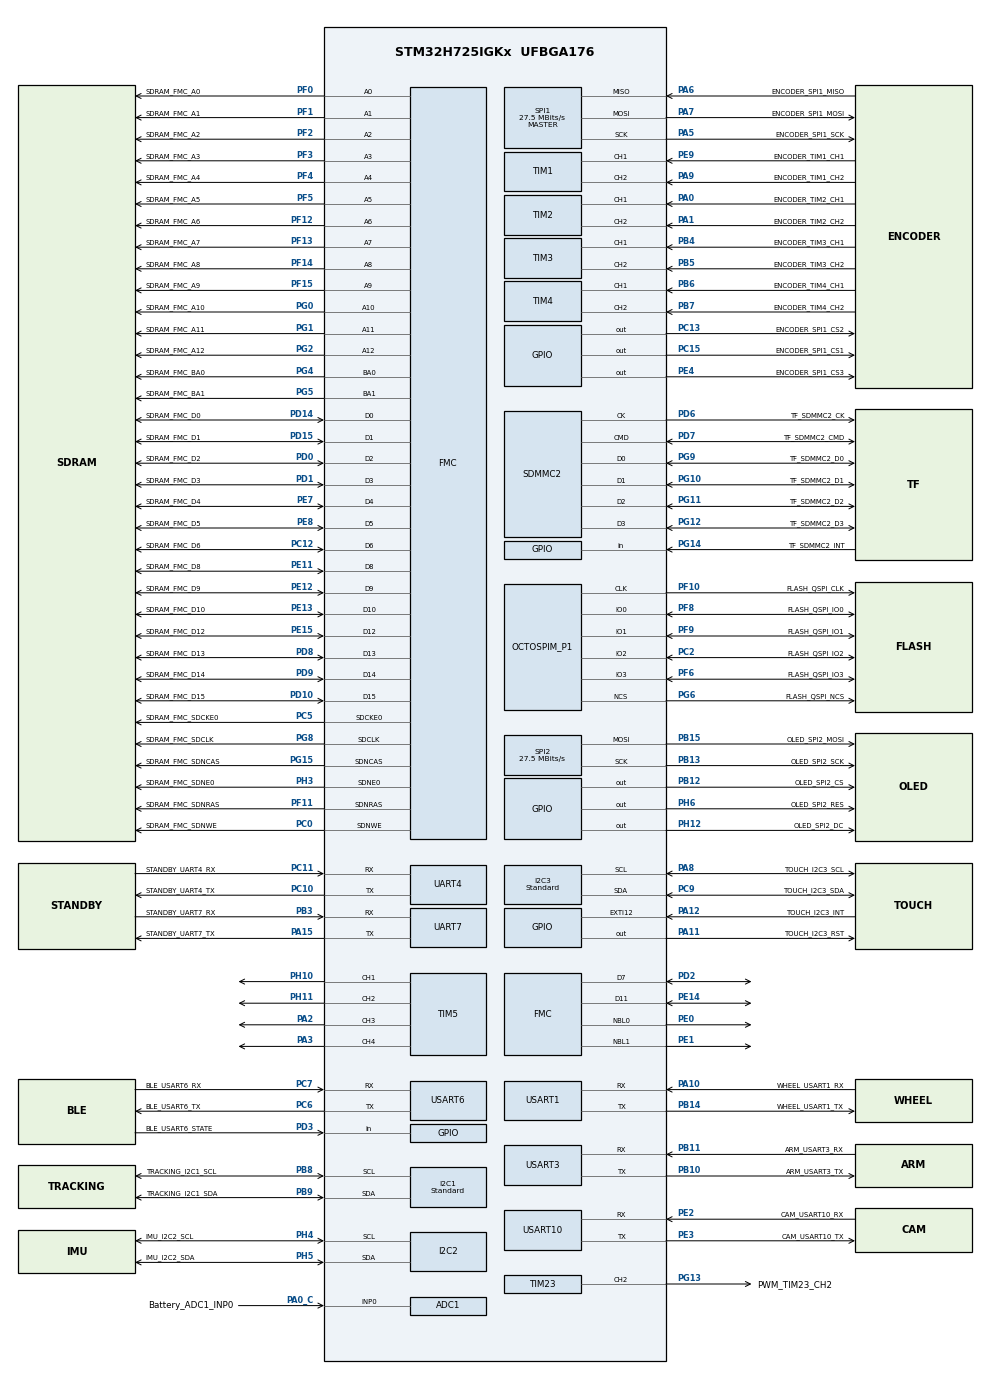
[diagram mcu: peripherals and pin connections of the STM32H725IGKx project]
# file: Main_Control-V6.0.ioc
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ADC1.Channel-0\#ChannelRegularConversion=ADC_CHANNEL_0
ADC1.ContinuousConvMode=ENABLE
ADC1.LowPowerAutoWait=ENABLE
ADC1.NbrOfConversionFlag=1
ADC1.OffsetNumber-0\#ChannelRegularConversion=ADC_OFFSET_NONE
ADC1.OffsetSignedSaturation-0\#ChannelRegularConversion=DISABLE
ADC1.Rank-0\#ChannelRegularConversion=1
ADC1.SamplingTime-0\#ChannelRegularConversion=ADC_SAMPLETIME_810CYCLES_5
ADC1.master=1
Dma.ADC1.8.Direction=DMA_PERIPH_TO_MEMORY
Dma.ADC1.8.EventEnable=DISABLE
Dma.ADC1.8.FIFOMode=DMA_FIFOMODE_DISABLE
Dma.ADC1.8.Instance=DMA2_Stream2
Dma.ADC1.8.MemDataAlignment=DMA_MDATAALIGN_HALFWORD
Dma.ADC1.8.MemInc=DMA_MINC_ENABLE
Dma.ADC1.8.Mode=DMA_CIRCULAR
Dma.ADC1.8.PeriphDataAlignment=DMA_PDATAALIGN_HALFWORD
Dma.ADC1.8.PeriphInc=DMA_PINC_DISABLE
Dma.ADC1.8.Polarity=HAL_DMAMUX_REQ_GEN_RISING
Dma.ADC1.8.Priority=DMA_PRIORITY_LOW
Dma.ADC1.8.RequestNumber=1
Dma.ADC1.8.SignalID=NONE
Dma.ADC1.8.SyncEnable=DISABLE
Dma.ADC1.8.SyncPolarity=HAL_DMAMUX_SYNC_NO_EVENT
Dma.ADC1.8.SyncRequestNumber=1
Dma.ADC1.8.SyncSignalID=NONE
Dma.I2C1_RX.1.Direction=DMA_PERIPH_TO_MEMORY
Dma.I2C1_RX.1.EventEnable=DISABLE
Dma.I2C1_RX.1.FIFOMode=DMA_FIFOMODE_DISABLE
Dma.I2C1_RX.1.Instance=DMA1_Stream1
Dma.I2C1_RX.1.MemDataAlignment=DMA_MDATAALIGN_BYTE
Dma.I2C1_RX.1.MemInc=DMA_MINC_ENABLE
Dma.I2C1_RX.1.Mode=DMA_NORMAL
Dma.I2C1_RX.1.PeriphDataAlignment=DMA_PDATAALIGN_BYTE
Dma.I2C1_RX.1.PeriphInc=DMA_PINC_DISABLE
Dma.I2C1_RX.1.Polarity=HAL_DMAMUX_REQ_GEN_RISING
Dma.I2C1_RX.1.Priority=DMA_PRIORITY_LOW
Dma.I2C1_RX.1.RequestNumber=1
Dma.I2C1_RX.1.SignalID=NONE
Dma.I2C1_RX.1.SyncEnable=DISABLE
Dma.I2C1_RX.1.SyncPolarity=HAL_DMAMUX_SYNC_NO_EVENT
Dma.I2C1_RX.1.SyncRequestNumber=1
Dma.I2C1_RX.1.SyncSignalID=NONE
Dma.I2C1_TX.0.Direction=DMA_MEMORY_TO_PERIPH
Dma.I2C1_TX.0.EventEnable=DISABLE
Dma.I2C1_TX.0.FIFOMode=DMA_FIFOMODE_DISABLE
Dma.I2C1_TX.0.Instance=DMA1_Stream0
Dma.I2C1_TX.0.MemDataAlignment=DMA_MDATAALIGN_BYTE
Dma.I2C1_TX.0.MemInc=DMA_MINC_ENABLE
Dma.I2C1_TX.0.Mode=DMA_NORMAL
Dma.I2C1_TX.0.PeriphDataAlignment=DMA_PDATAALIGN_BYTE
Dma.I2C1_TX.0.PeriphInc=DMA_PINC_DISABLE
Dma.I2C1_TX.0.Polarity=HAL_DMAMUX_REQ_GEN_RISING
Dma.I2C1_TX.0.Priority=DMA_PRIORITY_LOW
Dma.I2C1_TX.0.RequestNumber=1
Dma.I2C1_TX.0.SignalID=NONE
Dma.I2C1_TX.0.SyncEnable=DISABLE
Dma.I2C1_TX.0.SyncPolarity=HAL_DMAMUX_SYNC_NO_EVENT
Dma.I2C1_TX.0.SyncRequestNumber=1
Dma.I2C1_TX.0.SyncSignalID=NONE
Dma.I2C2_RX.3.Direction=DMA_PERIPH_TO_MEMORY
Dma.I2C2_RX.3.EventEnable=DISABLE
Dma.I2C2_RX.3.FIFOMode=DMA_FIFOMODE_DISABLE
Dma.I2C2_RX.3.Instance=DMA1_Stream3
Dma.I2C2_RX.3.MemDataAlignment=DMA_MDATAALIGN_BYTE
Dma.I2C2_RX.3.MemInc=DMA_MINC_ENABLE
Dma.I2C2_RX.3.Mode=DMA_NORMAL
Dma.I2C2_RX.3.PeriphDataAlignment=DMA_PDATAALIGN_BYTE
Dma.I2C2_RX.3.PeriphInc=DMA_PINC_DISABLE
Dma.I2C2_RX.3.Polarity=HAL_DMAMUX_REQ_GEN_RISING
Dma.I2C2_RX.3.Priority=DMA_PRIORITY_LOW
Dma.I2C2_RX.3.RequestNumber=1
Dma.I2C2_RX.3.SignalID=NONE
Dma.I2C2_RX.3.SyncEnable=DISABLE
Dma.I2C2_RX.3.SyncPolarity=HAL_DMAMUX_SYNC_NO_EVENT
Dma.I2C2_RX.3.SyncRequestNumber=1
Dma.I2C2_RX.3.SyncSignalID=NONE
Dma.I2C2_TX.2.Direction=DMA_MEMORY_TO_PERIPH
Dma.I2C2_TX.2.EventEnable=DISABLE
Dma.I2C2_TX.2.FIFOMode=DMA_FIFOMODE_DISABLE
Dma.I2C2_TX.2.Instance=DMA1_Stream2
Dma.I2C2_TX.2.MemDataAlignment=DMA_MDATAALIGN_BYTE
Dma.I2C2_TX.2.MemInc=DMA_MINC_ENABLE
Dma.I2C2_TX.2.Mode=DMA_NORMAL
Dma.I2C2_TX.2.PeriphDataAlignment=DMA_PDATAALIGN_BYTE
Dma.I2C2_TX.2.PeriphInc=DMA_PINC_DISABLE
Dma.I2C2_TX.2.Polarity=HAL_DMAMUX_REQ_GEN_RISING
Dma.I2C2_TX.2.Priority=DMA_PRIORITY_LOW
Dma.I2C2_TX.2.RequestNumber=1
Dma.I2C2_TX.2.SignalID=NONE
Dma.I2C2_TX.2.SyncEnable=DISABLE
Dma.I2C2_TX.2.SyncPolarity=HAL_DMAMUX_SYNC_NO_EVENT
Dma.I2C2_TX.2.SyncRequestNumber=1
Dma.I2C2_TX.2.SyncSignalID=NONE
Dma.Request0=I2C1_TX
Dma.Request1=I2C1_RX
Dma.Request10=USART10_RX
Dma.Request2=I2C2_TX
Dma.Request3=I2C2_RX
Dma.Request4=SPI1_TX
Dma.Request5=SPI1_RX
Dma.Request6=SPI2_TX
Dma.Request7=USART6_RX
Dma.Request8=ADC1
Dma.Request9=USART10_TX
Dma.SPI1_RX.5.Direction=DMA_PERIPH_TO_MEMORY
Dma.SPI1_RX.5.EventEnable=DISABLE
Dma.SPI1_RX.5.FIFOMode=DMA_FIFOMODE_DISABLE
Dma.SPI1_RX.5.Instance=DMA1_Stream5
Dma.SPI1_RX.5.MemDataAlignment=DMA_MDATAALIGN_BYTE
Dma.SPI1_RX.5.MemInc=DMA_MINC_ENABLE
Dma.SPI1_RX.5.Mode=DMA_NORMAL
Dma.SPI1_RX.5.PeriphDataAlignment=DMA_PDATAALIGN_BYTE
Dma.SPI1_RX.5.PeriphInc=DMA_PINC_DISABLE
Dma.SPI1_RX.5.Polarity=HAL_DMAMUX_REQ_GEN_RISING
Dma.SPI1_RX.5.Priority=DMA_PRIORITY_LOW
Dma.SPI1_RX.5.RequestNumber=1
Dma.SPI1_RX.5.SignalID=NONE
Dma.SPI1_RX.5.SyncEnable=DISABLE
Dma.SPI1_RX.5.SyncPolarity=HAL_DMAMUX_SYNC_NO_EVENT
Dma.SPI1_RX.5.SyncRequestNumber=1
Dma.SPI1_RX.5.SyncSignalID=NONE
Dma.SPI1_TX.4.Direction=DMA_MEMORY_TO_PERIPH
Dma.SPI1_TX.4.EventEnable=DISABLE
Dma.SPI1_TX.4.FIFOMode=DMA_FIFOMODE_DISABLE
Dma.SPI1_TX.4.Instance=DMA1_Stream4
Dma.SPI1_TX.4.MemDataAlignment=DMA_MDATAALIGN_BYTE
Dma.SPI1_TX.4.MemInc=DMA_MINC_ENABLE
Dma.SPI1_TX.4.Mode=DMA_NORMAL
Dma.SPI1_TX.4.PeriphDataAlignment=DMA_PDATAALIGN_BYTE
Dma.SPI1_TX.4.PeriphInc=DMA_PINC_DISABLE
Dma.SPI1_TX.4.Polarity=HAL_DMAMUX_REQ_GEN_RISING
Dma.SPI1_TX.4.Priority=DMA_PRIORITY_LOW
Dma.SPI1_TX.4.RequestNumber=1
Dma.SPI1_TX.4.SignalID=NONE
Dma.SPI1_TX.4.SyncEnable=DISABLE
Dma.SPI1_TX.4.SyncPolarity=HAL_DMAMUX_SYNC_NO_EVENT
Dma.SPI1_TX.4.SyncRequestNumber=1
Dma.SPI1_TX.4.SyncSignalID=NONE
Dma.SPI2_TX.6.Direction=DMA_MEMORY_TO_PERIPH
Dma.SPI2_TX.6.EventEnable=DISABLE
Dma.SPI2_TX.6.FIFOMode=DMA_FIFOMODE_DISABLE
Dma.SPI2_TX.6.Instance=DMA2_Stream0
Dma.SPI2_TX.6.MemDataAlignment=DMA_MDATAALIGN_HALFWORD
Dma.SPI2_TX.6.MemInc=DMA_MINC_ENABLE
Dma.SPI2_TX.6.Mode=DMA_NORMAL
Dma.SPI2_TX.6.PeriphDataAlignment=DMA_PDATAALIGN_HALFWORD
Dma.SPI2_TX.6.PeriphInc=DMA_PINC_DISABLE
Dma.SPI2_TX.6.Polarity=HAL_DMAMUX_REQ_GEN_RISING
Dma.SPI2_TX.6.Priority=DMA_PRIORITY_LOW
Dma.SPI2_TX.6.RequestNumber=1
Dma.SPI2_TX.6.SignalID=NONE
Dma.SPI2_TX.6.SyncEnable=DISABLE
Dma.SPI2_TX.6.SyncPolarity=HAL_DMAMUX_SYNC_NO_EVENT
Dma.SPI2_TX.6.SyncRequestNumber=1
Dma.SPI2_TX.6.SyncSignalID=NONE
Dma.USART10_RX.10.Direction=DMA_PERIPH_TO_MEMORY
Dma.USART10_RX.10.EventEnable=DISABLE
Dma.USART10_RX.10.FIFOMode=DMA_FIFOMODE_DISABLE
Dma.USART10_RX.10.Instance=DMA2_Stream7
Dma.USART10_RX.10.MemDataAlignment=DMA_MDATAALIGN_BYTE
Dma.USART10_RX.10.MemInc=DMA_MINC_ENABLE
Dma.USART10_RX.10.Mode=DMA_NORMAL
Dma.USART10_RX.10.PeriphDataAlignment=DMA_PDATAALIGN_BYTE
Dma.USART10_RX.10.PeriphInc=DMA_PINC_DISABLE
Dma.USART10_RX.10.Polarity=HAL_DMAMUX_REQ_GEN_RISING
Dma.USART10_RX.10.Priority=DMA_PRIORITY_LOW
Dma.USART10_RX.10.RequestNumber=1
Dma.USART10_RX.10.SignalID=NONE
Dma.USART10_RX.10.SyncEnable=DISABLE
Dma.USART10_RX.10.SyncPolarity=HAL_DMAMUX_SYNC_NO_EVENT
Dma.USART10_RX.10.SyncRequestNumber=1
Dma.USART10_RX.10.SyncSignalID=NONE
Dma.USART10_TX.9.Direction=DMA_MEMORY_TO_PERIPH
Dma.USART10_TX.9.EventEnable=DISABLE
Dma.USART10_TX.9.FIFOMode=DMA_FIFOMODE_DISABLE
Dma.USART10_TX.9.Instance=DMA1_Stream6
Dma.USART10_TX.9.MemDataAlignment=DMA_MDATAALIGN_BYTE
Dma.USART10_TX.9.MemInc=DMA_MINC_ENABLE
Dma.USART10_TX.9.Mode=DMA_NORMAL
Dma.USART10_TX.9.PeriphDataAlignment=DMA_PDATAALIGN_BYTE
Dma.USART10_TX.9.PeriphInc=DMA_PINC_DISABLE
Dma.USART10_TX.9.Polarity=HAL_DMAMUX_REQ_GEN_RISING
Dma.USART10_TX.9.Priority=DMA_PRIORITY_LOW
Dma.USART10_TX.9.RequestNumber=1
Dma.USART10_TX.9.SignalID=NONE
Dma.USART10_TX.9.SyncEnable=DISABLE
Dma.USART10_TX.9.SyncPolarity=HAL_DMAMUX_SYNC_NO_EVENT
Dma.USART10_TX.9.SyncRequestNumber=1
Dma.USART10_TX.9.SyncSignalID=NONE
Dma.USART6_RX.7.Direction=DMA_PERIPH_TO_MEMORY
Dma.USART6_RX.7.EventEnable=DISABLE
Dma.USART6_RX.7.FIFOMode=DMA_FIFOMODE_DISABLE
Dma.USART6_RX.7.Instance=DMA2_Stream1
Dma.USART6_RX.7.MemDataAlignment=DMA_MDATAALIGN_BYTE
Dma.USART6_RX.7.MemInc=DMA_MINC_ENABLE
Dma.USART6_RX.7.Mode=DMA_CIRCULAR
Dma.USART6_RX.7.PeriphDataAlignment=DMA_PDATAALIGN_BYTE
Dma.USART6_RX.7.PeriphInc=DMA_PINC_DISABLE
Dma.USART6_RX.7.Polarity=HAL_DMAMUX_REQ_GEN_RISING
Dma.USART6_RX.7.Priority=DMA_PRIORITY_LOW
Dma.USART6_RX.7.RequestNumber=1
Dma.USART6_RX.7.SignalID=NONE
Dma.USART6_RX.7.SyncEnable=DISABLE
Dma.USART6_RX.7.SyncPolarity=HAL_DMAMUX_SYNC_NO_EVENT
Dma.USART6_RX.7.SyncRequestNumber=1
Dma.USART6_RX.7.SyncSignalID=NONE
FATFS.BSP.number=1
FATFS.USE_DMA_CODE_SD=1
FATFS._CODE_PAGE=936
FATFS._USE_LFN=2
FATFS0.BSP.STBoard=false
FATFS0.BSP.api=Unknown
FATFS0.BSP.instance=PG14
FATFS0.BSP.ip=GPIO
FATFS0.BSP.mode=Input
FATFS0.BSP.name=Detect_SDIO
FATFS0.BSP.solution=PG14
FMC.BankMapConfig=FMC_SWAPBMAP_DISABLE
FMC.CASLatency1=FMC_SDRAM_CAS_LATENCY_3
FMC.ColumnBitsNumber1=FMC_SDRAM_COLUMN_BITS_NUM_9
FMC.ExitSelfRefreshDelay1=10
FMC.LoadToActiveDelay1=2
FMC.RCDDelay1=3
FMC.RPDelay1=3
FMC.ReadBurst1=FMC_SDRAM_RBURST_ENABLE
FMC.ReadPipeDelay1=FMC_SDRAM_RPIPE_DELAY_1
FMC.RowCycleDelay1=9
FMC.SDClockPeriod1=FMC_SDRAM_CLOCK_PERIOD_2
FMC.SelfRefreshTime1=6
FMC.WriteRecoveryTime1=4
I2C1.I2C_Speed_Mode=I2C_Standard
I2C1.Timing=0x60404E72
I2C2.Timing=0x60404E72
I2C3.Analog_Filter=I2C_ANALOGFILTER_ENABLE
I2C3.CustomTiming=Disabled
I2C3.I2C_Speed_Mode=I2C_Standard
I2C3.Speed=100
I2C3.Timing=0x60404E72
Mcu.Family=STM32H7
Mcu.Name=STM32H725IGKx
Mcu.Package=UFBGA176
NVIC.DMA1_Stream0_IRQn=true\:1\:0\:true\:false\:true\:false\:true\:true
NVIC.DMA1_Stream1_IRQn=true\:1\:0\:true\:false\:true\:false\:true\:true
NVIC.DMA1_Stream2_IRQn=true\:2\:0\:true\:false\:true\:false\:true\:true
NVIC.DMA1_Stream3_IRQn=true\:2\:0\:true\:false\:true\:false\:true\:true
NVIC.DMA1_Stream4_IRQn=true\:3\:0\:true\:false\:true\:false\:true\:true
NVIC.DMA1_Stream5_IRQn=true\:3\:0\:true\:false\:true\:false\:true\:true
NVIC.DMA1_Stream6_IRQn=true\:4\:0\:true\:false\:true\:false\:true\:true
NVIC.DMA2_Stream0_IRQn=true\:14\:0\:true\:false\:true\:false\:true\:true
NVIC.DMA2_Stream1_IRQn=true\:5\:0\:true\:false\:true\:false\:true\:true
NVIC.DMA2_Stream2_IRQn=true\:13\:0\:true\:false\:true\:false\:true\:true
NVIC.DMA2_Stream7_IRQn=true\:4\:0\:true\:false\:true\:false\:true\:true
NVIC.EXTI15_10_IRQn=true\:14\:0\:true\:false\:true\:true\:true\:true
NVIC.I2C1_ER_IRQn=true\:1\:0\:true\:false\:true\:true\:true\:true
NVIC.I2C1_EV_IRQn=true\:1\:0\:true\:false\:true\:true\:true\:true
NVIC.I2C2_ER_IRQn=true\:2\:0\:true\:false\:true\:true\:true\:true
NVIC.I2C2_EV_IRQn=true\:2\:0\:true\:false\:true\:true\:true\:true
NVIC.PriorityGroup=NVIC_PRIORITYGROUP_4
NVIC.SPI1_IRQn=true\:3\:0\:true\:false\:true\:false\:true\:true
NVIC.SPI2_IRQn=true\:14\:0\:true\:false\:true\:false\:true\:true
NVIC.TIM6_DAC_IRQn=true\:14\:0\:true\:false\:true\:true\:true\:true
NVIC.USART10_IRQn=true\:4\:0\:true\:false\:true\:true\:true\:true
NVIC.USART6_IRQn=true\:5\:0\:true\:false\:true\:true\:true\:true
OCTOSPI1.ChipSelectBoundary=0
OCTOSPI1.ChipSelectHighTime=7
OCTOSPI1.ClockPrescaler=1
OCTOSPI1.DelayHoldQuarterCycle=HAL_OSPI_DHQC_DISABLE
OCTOSPI1.DeviceSize=25
OCTOSPI1.FifoThreshold=1
OCTOSPI1.MaxTran=0
OCTOSPI1.MemoryType=HAL_OSPI_MEMTYPE_MICRON
OCTOSPI1.Refresh=0
OCTOSPI1.SampleShifting=HAL_OSPI_SAMPLE_SHIFTING_HALFCYCLE
OCTOSPI1.WrapSize=HAL_OSPI_WRAP_NOT_SUPPORTED
PA0.GPIO_Label=ENCODER_TIM2_CH1
PA0.Signal=S_TIM2_CH1_ETR
PA0_C.GPIO_Label=Battery_ADC1_INP0
PA0_C.Signal=ADCx_INP0
PA1.GPIO_Label=ENCODER_TIM2_CH2
PA1.Signal=S_TIM2_CH2
PA10.GPIO_Label=WHEEL_USART1_RX
PA10.Mode=Asynchronous
PA10.Signal=USART1_RX
PA11.GPIO_Label=TOUCH_I2C3_RST
PA11.GPIO_PuPd=GPIO_PULLUP
PA11.Signal=GPIO_Output
PA12.GPIO_Label=TOUCH_I2C3_INT
PA12.GPIO_ModeDefaultEXTI=GPIO_MODE_IT_FALLING
PA12.GPIO_PuPd=GPIO_NOPULL
PA12.Signal=GPXTI12
PA13(JTMS/SWDIO).Mode=Serial_Wire
PA13(JTMS/SWDIO).Signal=DEBUG_JTMS-SWDIO
PA14(JTCK/SWCLK).Mode=Serial_Wire
PA14(JTCK/SWCLK).Signal=DEBUG_JTCK-SWCLK
PA15(JTDI).GPIO_Label=STANDBY_UART7_TX
PA15(JTDI).Mode=Asynchronous
PA15(JTDI).Signal=UART7_TX
PA2.Signal=S_TIM5_CH3
PA3.Signal=S_TIM5_CH4
PA5.GPIO_Label=ENCODER_SPI1_SCK
PA5.Mode=Full_Duplex_Master
PA5.Signal=SPI1_SCK
PA6.GPIO_Label=ENCODER_SPI1_MISO
PA6.Mode=Full_Duplex_Master
PA6.Signal=SPI1_MISO
PA7.GPIO_Label=ENCODER_SPI1_MOSI
PA7.Mode=Full_Duplex_Master
PA7.Signal=SPI1_MOSI
PA8.GPIO_Label=TOUCH_I2C3_SCL
PA8.GPIO_Speed=GPIO_SPEED_FREQ_VERY_HIGH
PA8.Mode=I2C
PA8.Signal=I2C3_SCL
PA9.GPIO_Label=ENCODER_TIM1_CH2
PA9.Signal=S_TIM1_CH2
PB10.GPIO_Label=ARM_USART3_TX
PB10.Mode=Asynchronous
PB10.Signal=USART3_TX
PB11.GPIO_Label=ARM_USART3_RX
PB11.Mode=Asynchronous
PB11.Signal=USART3_RX
PB12.GPIO_Label=OLED_SPI2_CS
PB12.GPIO_ModeDefaultOutputPP=GPIO_MODE_OUTPUT_PP
PB12.GPIO_PuPd=GPIO_PULLUP
PB12.GPIO_Speed=GPIO_SPEED_FREQ_VERY_HIGH
PB12.PinState=GPIO_PIN_SET
PB12.Signal=GPIO_Output
PB13.GPIO_Label=OLED_SPI2_SCK
PB13.Mode=TX_Only_Simplex_Unidirect_Master
PB13.Signal=SPI2_SCK
PB14.GPIO_Label=WHEEL_USART1_TX
PB14.Mode=Asynchronous
PB14.Signal=USART1_TX
PB15.GPIO_Label=OLED_SPI2_MOSI
PB15.Mode=TX_Only_Simplex_Unidirect_Master
PB15.Signal=SPI2_MOSI
PB3(JTDO/TRACESWO).GPIO_Label=STANDBY_UART7_RX
PB3(JTDO/TRACESWO).Mode=Asynchronous
PB3(JTDO/TRACESWO).Signal=UART7_RX
PB4(NJTRST).GPIO_Label=ENCODER_TIM3_CH1
PB4(NJTRST).Signal=S_TIM3_CH1
PB5.GPIO_Label=ENCODER_TIM3_CH2
PB5.Signal=S_TIM3_CH2
PB6.GPIO_Label=ENCODER_TIM4_CH1
PB6.Signal=S_TIM4_CH1
PB7.GPIO_Label=ENCODER_TIM4_CH2
PB7.Signal=S_TIM4_CH2
PB8.GPIO_Label=TRACKING_I2C1_SCL
PB8.Mode=I2C
PB8.Signal=I2C1_SCL
PB9.GPIO_Label=TRACKING_I2C1_SDA
PB9.Mode=I2C
PB9.Signal=I2C1_SDA
PC0.GPIO_Label=SDRAM_FMC_SDNWE
PC0.Signal=FMC_SDNWE
PC10.GPIO_Label=STANDBY_UART4_TX
PC10.Mode=Asynchronous
PC10.Signal=UART4_TX
PC11.GPIO_Label=STANDBY_UART4_RX
PC11.Mode=Asynchronous
PC11.Signal=UART4_RX
PC12.GPIO_Label=SDRAM_FMC_D6
PC12.Signal=FMC_D6_DA6
PC13.GPIO_Label=ENCODER_SPI1_CS2
PC13.Signal=GPIO_Output
PC15-OSC32_OUT.GPIO_Label=ENCODER_SPI1_CS1
PC15-OSC32_OUT.Signal=GPIO_Output
PC2.GPIO_Label=FLASH_QSPI_IO2
PC2.Mode=OCTOSPI1_IOL_Port1L
PC2.Signal=OCTOSPIM_P1_IO2
PC5.GPIO_Label=SDRAM_FMC_SDCKE0
PC5.Mode=SdramChipSelect1_1
PC5.Signal=FMC_SDCKE0
PC6.GPIO_Label=BLE_USART6_TX
PC6.Mode=Asynchronous
PC6.Signal=USART6_TX
PC7.GPIO_Label=BLE_USART6_RX
PC7.Mode=Asynchronous
PC7.Signal=USART6_RX
PC9.GPIO_Label=TOUCH_I2C3_SDA
PC9.GPIO_Speed=GPIO_SPEED_FREQ_VERY_HIGH
PC9.Mode=I2C
PC9.Signal=I2C3_SDA
PD0.GPIO_Label=SDRAM_FMC_D2
PD0.Signal=FMC_D2_DA2
PD1.GPIO_Label=SDRAM_FMC_D3
PD1.Signal=FMC_D3_DA3
PD10.GPIO_Label=SDRAM_FMC_D15
PD10.Signal=FMC_D15_DA15
PD14.GPIO_Label=SDRAM_FMC_D0
PD14.Signal=FMC_D0_DA0
PD15.GPIO_Label=SDRAM_FMC_D1
PD15.Signal=FMC_D1_DA1
PD2.Signal=FMC_D7_DA7
PD3.GPIO_Label=BLE_USART6_STATE
PD3.Signal=GPIO_Input
PD6.GPIO_Label=TF_SDMMC2_CK
PD6.Mode=SD_4_bits_Wide_bus
PD6.Signal=SDMMC2_CK
PD7.GPIO_Label=TF_SDMMC2_CMD
PD7.Mode=SD_4_bits_Wide_bus
PD7.Signal=SDMMC2_CMD
PD8.GPIO_Label=SDRAM_FMC_D13
PD8.Signal=FMC_D13_DA13
PD9.GPIO_Label=SDRAM_FMC_D14
PD9.Signal=FMC_D14_DA14
PE0.Signal=FMC_NBL0
PE1.Signal=FMC_NBL1
PE11.GPIO_Label=SDRAM_FMC_D8
PE11.Signal=FMC_D8_DA8
PE12.GPIO_Label=SDRAM_FMC_D9
PE12.Signal=FMC_D9_DA9
PE13.GPIO_Label=SDRAM_FMC_D10
PE13.Signal=FMC_D10_DA10
PE14.Signal=FMC_D11_DA11
PE15.GPIO_Label=SDRAM_FMC_D12
PE15.Signal=FMC_D12_DA12
PE2.GPIO_Label=CAM_USART10_RX
PE2.Mode=Asynchronous
PE2.Signal=USART10_RX
PE3.GPIO_Label=CAM_USART10_TX
PE3.Mode=Asynchronous
PE3.Signal=USART10_TX
PE4.GPIO_Label=ENCODER_SPI1_CS3
PE4.Signal=GPIO_Output
PE7.GPIO_Label=SDRAM_FMC_D4
PE7.Signal=FMC_D4_DA4
PE8.GPIO_Label=SDRAM_FMC_D5
PE8.Signal=FMC_D5_DA5
PE9.GPIO_Label=ENCODER_TIM1_CH1
PE9.Signal=S_TIM1_CH1
PF0.GPIO_Label=SDRAM_FMC_A0
PF0.Signal=FMC_A0
PF1.GPIO_Label=SDRAM_FMC_A1
PF1.Signal=FMC_A1
PF10.GPIO_Label=FLASH_QSPI_CLK
PF10.Mode=O1_P1_CLK
PF10.Signal=OCTOSPIM_P1_CLK
PF11.GPIO_Label=SDRAM_FMC_SDNRAS
PF11.Signal=FMC_SDNRAS
PF12.GPIO_Label=SDRAM_FMC_A6
PF12.Signal=FMC_A6
PF13.GPIO_Label=SDRAM_FMC_A7
PF13.Signal=FMC_A7
PF14.GPIO_Label=SDRAM_FMC_A8
PF14.Signal=FMC_A8
PF15.GPIO_Label=SDRAM_FMC_A9
PF15.Signal=FMC_A9
PF2.GPIO_Label=SDRAM_FMC_A2
PF2.Signal=FMC_A2
PF3.GPIO_Label=SDRAM_FMC_A3
PF3.Signal=FMC_A3
PF4.GPIO_Label=SDRAM_FMC_A4
PF4.Signal=FMC_A4
PF5.GPIO_Label=SDRAM_FMC_A5
PF5.Signal=FMC_A5
PF6.GPIO_Label=FLASH_QSPI_IO3
PF6.Mode=OCTOSPI1_IOL_Port1L
PF6.Signal=OCTOSPIM_P1_IO3
PF8.GPIO_Label=FLASH_QSPI_IO0
PF8.Mode=OCTOSPI1_IOL_Port1L
PF8.Signal=OCTOSPIM_P1_IO0
PF9.GPIO_Label=FLASH_QSPI_IO1
PF9.Mode=OCTOSPI1_IOL_Port1L
PF9.Signal=OCTOSPIM_P1_IO1
PG0.GPIO_Label=SDRAM_FMC_A10
PG0.Signal=FMC_A10
PG1.GPIO_Label=SDRAM_FMC_A11
PG1.Signal=FMC_A11
PG10.GPIO_Label=TF_SDMMC2_D1
PG10.Mode=SD_4_bits_Wide_bus
PG10.Signal=SDMMC2_D1
PG11.GPIO_Label=TF_SDMMC2_D2
PG11.Mode=SD_4_bits_Wide_bus
PG11.Signal=SDMMC2_D2
PG12.GPIO_Label=TF_SDMMC2_D3
PG12.Mode=SD_4_bits_Wide_bus
PG12.Signal=SDMMC2_D3
PG13.GPIO_Label=PWM_TIM23_CH2
PG13.Signal=S_TIM23_CH2
PG14.GPIO_Label=TF_SDMMC2_INT
PG14.Signal=GPIO_Input
PG15.GPIO_Label=SDRAM_FMC_SDNCAS
PG15.Signal=FMC_SDNCAS
PG2.GPIO_Label=SDRAM_FMC_A12
PG2.Signal=FMC_A12
PG4.GPIO_Label=SDRAM_FMC_BA0
PG4.Signal=FMC_A14_BA0
PG5.GPIO_Label=SDRAM_FMC_BA1
PG5.Signal=FMC_A15_BA1
PG6.GPIO_Label=FLASH_QSPI_NCS
PG6.GPIO_PuPd=GPIO_PULLUP
PG6.Mode=OCTOSPI1_Port1_NCS
PG6.Signal=OCTOSPIM_P1_NCS
PG8.GPIO_Label=SDRAM_FMC_SDCLK
PG8.Signal=FMC_SDCLK
PG9.GPIO_Label=TF_SDMMC2_D0
PG9.Mode=SD_4_bits_Wide_bus
PG9.Signal=SDMMC2_D0
PH0-OSC_IN.Mode=HSE-External-Oscillator
PH0-OSC_IN.Signal=RCC_OSC_IN
PH1-OSC_OUT.Mode=HSE-External-Oscillator
PH1-OSC_OUT.Signal=RCC_OSC_OUT
PH10.Signal=S_TIM5_CH1
PH11.Signal=S_TIM5_CH2
PH12.GPIO_Label=OLED_SPI2_DC
PH12.GPIO_ModeDefaultOutputPP=GPIO_MODE_OUTPUT_PP
PH12.GPIO_PuPd=GPIO_PULLUP
PH12.GPIO_Speed=GPIO_SPEED_FREQ_VERY_HIGH
PH12.PinState=GPIO_PIN_SET
PH12.Signal=GPIO_Output
PH3.GPIO_Label=SDRAM_FMC_SDNE0
PH3.Mode=SdramChipSelect1_1
PH3.Signal=FMC_SDNE0
PH4.GPIO_Label=IMU_I2C2_SCL
PH4.Mode=I2C
PH4.Signal=I2C2_SCL
PH5.GPIO_Label=IMU_I2C2_SDA
PH5.Mode=I2C
PH5.Signal=I2C2_SDA
PH6.GPIO_Label=OLED_SPI2_RES
PH6.GPIO_ModeDefaultOutputPP=GPIO_MODE_OUTPUT_PP
PH6.GPIO_PuPd=GPIO_PULLUP
PH6.GPIO_Speed=GPIO_SPEED_FREQ_LOW
PH6.Signal=GPIO_Output
ProjectManager.HeapSize=0x2000
ProjectManager.StackSize=0x4000
ProjectManager.TargetToolchain=MDK-ARM V5.32
RCC.ADCCLockSelection=RCC_ADCCLKSOURCE_CLKP
RCC.ADCFreq_Value=64000000
RCC.APB1Freq_Value=137500000
RCC.APB2Freq_Value=137500000
RCC.APB3Freq_Value=137500000
RCC.APB4Freq_Value=137500000
RCC.CortexFreq_Value=550000000
RCC.D1PPRE=RCC_APB3_DIV2
RCC.D2PPRE1=RCC_APB1_DIV2
RCC.D2PPRE2=RCC_APB2_DIV2
RCC.D3PPRE=RCC_APB4_DIV2
RCC.DIVM1=5
RCC.DIVM2=5
RCC.DIVM3=5
RCC.DIVN1=110
RCC.DIVN2=133
RCC.DIVN3=100
RCC.DIVP1=1
RCC.DIVP2=5
RCC.DIVP3=5
RCC.DIVQ1=10
RCC.DIVQ2=5
RCC.DIVQ3=5
RCC.DIVR2=5
RCC.DIVR3=5
RCC.EnbaleCSS=false
RCC.FLatency-AdvancedSettings=FLASH_LATENCY_3
RCC.HCLKFreq_Value=275000000
RCC.HPRE=RCC_HCLK_DIV2
RCC.HSE_VALUE=25000000
RCC.PLL1_VCI_Range-AdvancedSettings=RCC_PLL1VCIRANGE_3
RCC.PLL1_VCO_SEL-AdvancedSettings=RCC_PLL1VCOMEDIUM
RCC.PLL2FRACN=0
RCC.PLL2_VCI_Range-AdvancedSettings=RCC_PLL2VCIRANGE_3
RCC.PLL2_VCO_SEL-AdvancedSettings=RCC_PLL2VCOMEDIUM
RCC.PLL3_VCI_Range-AdvancedSettings=RCC_PLL3VCIRANGE_3
RCC.PLL3_VCO_SEL-AdvancedSettings=RCC_PLL3VCOMEDIUM
RCC.PLLFRACN=0
RCC.PLLSourceVirtual=RCC_PLLSOURCE_HSE
RCC.QSPICLockSelection=RCC_OSPICLKSOURCE_PLL2
RCC.SYSCLKFreq_VALUE=550000000
RCC.SYSCLKSource=RCC_SYSCLKSOURCE_PLLCLK
RCC.SupplySource=PWR_LDO_SUPPLY
RCC.USBFreq_Value=55000000
SH.ADCx_INP0.0=ADC1_INP0,IN0-Single-Ended
SH.FMC_A0.0=FMC_A0,13b-sda1
SH.FMC_A1.0=FMC_A1,13b-sda1
SH.FMC_A10.0=FMC_A10,13b-sda1
SH.FMC_A11.0=FMC_A11,13b-sda1
SH.FMC_A12.0=FMC_A12,13b-sda1
SH.FMC_A14_BA0.0=FMC_BA0,FourSdramBanks1
SH.FMC_A15_BA1.0=FMC_BA1,FourSdramBanks1
SH.FMC_A2.0=FMC_A2,13b-sda1
SH.FMC_A3.0=FMC_A3,13b-sda1
SH.FMC_A4.0=FMC_A4,13b-sda1
SH.FMC_A5.0=FMC_A5,13b-sda1
SH.FMC_A6.0=FMC_A6,13b-sda1
SH.FMC_A7.0=FMC_A7,13b-sda1
SH.FMC_A8.0=FMC_A8,13b-sda1
SH.FMC_A9.0=FMC_A9,13b-sda1
SH.FMC_D0_DA0.0=FMC_D0,sd-16b-d1
SH.FMC_D10_DA10.0=FMC_D10,sd-16b-d1
SH.FMC_D11_DA11.0=FMC_D11,sd-16b-d1
SH.FMC_D12_DA12.0=FMC_D12,sd-16b-d1
SH.FMC_D13_DA13.0=FMC_D13,sd-16b-d1
SH.FMC_D14_DA14.0=FMC_D14,sd-16b-d1
SH.FMC_D15_DA15.0=FMC_D15,sd-16b-d1
SH.FMC_D1_DA1.0=FMC_D1,sd-16b-d1
SH.FMC_D2_DA2.0=FMC_D2,sd-16b-d1
SH.FMC_D3_DA3.0=FMC_D3,sd-16b-d1
SH.FMC_D4_DA4.0=FMC_D4,sd-16b-d1
SH.FMC_D5_DA5.0=FMC_D5,sd-16b-d1
SH.FMC_D6_DA6.0=FMC_D6,sd-16b-d1
SH.FMC_D7_DA7.0=FMC_D7,sd-16b-d1
SH.FMC_D8_DA8.0=FMC_D8,sd-16b-d1
SH.FMC_D9_DA9.0=FMC_D9,sd-16b-d1
SH.FMC_NBL0.0=FMC_NBL0,Sd2ByteEnable1
SH.FMC_NBL1.0=FMC_NBL1,Sd2ByteEnable1
SH.FMC_SDCLK.0=FMC_SDCLK,13b-sda1
SH.FMC_SDNCAS.0=FMC_SDNCAS,13b-sda1
SH.FMC_SDNRAS.0=FMC_SDNRAS,13b-sda1
SH.FMC_SDNWE.0=FMC_SDNWE,13b-sda1
SH.S_TIM1_CH1.0=TIM1_CH1,Encoder_Interface
SH.S_TIM1_CH2.0=TIM1_CH2,Encoder_Interface
SH.S_TIM23_CH2.0=TIM23_CH2,PWM Generation2 CH2
SH.S_TIM2_CH1_ETR.0=TIM2_CH1,Encoder_Interface
SH.S_TIM2_CH2.0=TIM2_CH2,Encoder_Interface
SH.S_TIM3_CH1.0=TIM3_CH1,Encoder_Interface
SH.S_TIM3_CH2.0=TIM3_CH2,Encoder_Interface
SH.S_TIM4_CH1.0=TIM4_CH1,Encoder_Interface
SH.S_TIM4_CH2.0=TIM4_CH2,Encoder_Interface
SH.S_TIM5_CH1.0=TIM5_CH1,PWM Generation1 CH1
SH.S_TIM5_CH2.0=TIM5_CH2,PWM Generation2 CH2
SH.S_TIM5_CH3.0=TIM5_CH3,PWM Generation3 CH3
SH.S_TIM5_CH4.0=TIM5_CH4,PWM Generation4 CH4
SPI1.BaudRatePrescaler=SPI_BAUDRATEPRESCALER_2
SPI1.CalculateBaudRate=27.5 MBits/s
SPI1.Direction=SPI_DIRECTION_2LINES
SPI1.Mode=SPI_MODE_MASTER
SPI1.VirtualType=VM_MASTER
SPI2.BaudRatePrescaler=SPI_BAUDRATEPRESCALER_2
SPI2.CalculateBaudRate=27.5 MBits/s
SPI2.DataSize=SPI_DATASIZE_8BIT
SPI2.Direction=SPI_DIRECTION_2LINES_TXONLY
SPI2.Mode=SPI_MODE_MASTER
SPI2.NSSPMode=SPI_NSS_PULSE_DISABLE
SPI2.VirtualType=VM_MASTER
TIM23.Channel-PWM\ Generation2\ CH2=TIM_CHANNEL_2
TIM5.Channel-PWM\ Generation1\ CH1=TIM_CHANNEL_1
TIM5.Channel-PWM\ Generation2\ CH2=TIM_CHANNEL_2
TIM5.Channel-PWM\ Generation3\ CH3=TIM_CHANNEL_3
TIM5.Channel-PWM\ Generation4\ CH4=TIM_CHANNEL_4
TIM6.AutoReloadPreload=TIM_AUTORELOAD_PRELOAD_ENABLE
TIM6.Period=1000-1
TIM6.Prescaler=275-1
USART1.VirtualMode-Asynchronous=VM_ASYNC
USART10.VirtualMode-Asynchronous=VM_ASYNC
USART3.VirtualMode-Asynchronous=VM_ASYNC
USART6.VirtualMode-Asynchronous=VM_ASYNC
VP_FATFS_VS_SDIO.Mode=SDIO
VP_OCTOSPI1_VS_quad.Mode=quad_mode
VP_TIM23_VS_ClockSourceINT.Mode=Internal
VP_TIM6_VS_ClockSourceINT.Mode=Enable_Timer
board=custom

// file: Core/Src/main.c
/* USER CODE BEGIN Header */
/**
  ******************************************************************************
  * @file           : main.c
  * @brief          : Main program body
  ******************************************************************************
  * @attention
  *
  * Copyright (c) 2023 STMicroelectronics.
  * All rights reserved.
  *
  * This software is licensed under terms that can be found in the LICENSE file
  * in the root directory of this software component.
  * If no LICENSE file comes with this software, it is provided AS-IS.
  *
  ******************************************************************************
  */
/* USER CODE END Header */
#include "main.h"
#include "adc.h"
#include "dma.h"
#include "fatfs.h"
#include "i2c.h"
#include "octospi.h"
#include "sdmmc.h"
#include "spi.h"
#include "tim.h"
#include "usart.h"
#include "gpio.h"
#include "fmc.h"

/* USER CODE BEGIN Includes */
#include "sdram.h"
#include "Flash.h"
#include "string.h"
#include "ST7789V.h"
#include "GT911.h"
#include "lvgl.h"
#include "lv_port_disp.h"
#include "lv_port_indev.h"
//#include "lv_port_fs.h"
#include "lv_app.h"
/* USER CODE END Includes */

/* USER CODE BEGIN PV */
HAL_StatusTypeDef ret=0;
extern uint8_t reg1, reg2, reg3;
uint8_t ID[3];
uint8_t write[20];
uint8_t read[20]={0};
uint32_t* add=(uint32_t*)0x90000000+30;
/* USER CODE END PV */

void SystemClock_Config(void);
void PeriphCommonClock_Config(void);

/* USER CODE BEGIN 0 */
uint32_t time=0;
void HAL_TIM_PeriodElapsedCallback(TIM_HandleTypeDef *htim)
{
	if(htim == &htim6)//1000Hz;1ms
	{
		lv_tick_inc(1);
		time++;
	}
//  else if(htim == &htim6)//20Hz;50ms
//  {
//    PID_Calculate();
//    PID_Frequence_Detection();
//    BLE_Arm.Control_Sign = true;
//  }
}

void HAL_SPI_TxCpltCallback(SPI_HandleTypeDef *hspi)
{
	if(hspi == &hspi2)
	{
		if(hspi2.State == HAL_SPI_STATE_READY)
		{
			lv_disp_flush_ready(disp_drv_p);
			LCD_CS_H;
		}
	}
}

void HAL_GPIO_EXTI_Callback(uint16_t GPIO_Pin)
{
  if(GPIO_Pin == TOUCH_I2C3_INT_Pin)
  {
		gt911_Scanf();
		LCD_Draw_Point(User_Touch.Touch_XY[0].X_Point,User_Touch.Touch_XY[0].Y_Point,RED);
	}
}
/* USER CODE END 0 */

int main(void)
{

  /* MCU Configuration--------------------------------------------------------*/

  /* Reset of all peripherals, Initializes the Flash interface and the Systick. */
  HAL_Init();

  /* Configure the system clock */
  SystemClock_Config();

/* Configure the peripherals common clocks */
  PeriphCommonClock_Config();

  /* Initialize all configured peripherals */
  MX_GPIO_Init();
  MX_DMA_Init();
  MX_FMC_Init();
  MX_I2C1_Init();
  MX_I2C2_Init();
  MX_I2C3_Init();
  MX_OCTOSPI1_Init();
  MX_SDMMC2_SD_Init();
  MX_SPI1_Init();
  MX_SPI2_Init();
  MX_UART7_Init();
  MX_USART1_UART_Init();
  MX_USART3_UART_Init();
  MX_USART6_UART_Init();
  MX_USART10_UART_Init();
  MX_ADC1_Init();
  MX_FATFS_Init();
  MX_UART4_Init();
  MX_TIM23_Init();
  MX_TIM1_Init();
  MX_TIM2_Init();
  MX_TIM3_Init();
  MX_TIM4_Init();
  MX_TIM5_Init();
  MX_TIM6_Init();
  /* USER CODE BEGIN 2 */
//	ret=W25Q256_OCTO_SPI_Init(&hospi1);
//  ret=W25Q256_OSPI_EnableMemoryMappedMode(&hospi1);
//
//	SDRAM_Init(&hsdram1);
	///////////////////////////////////   LVGL_TIM_Init   /////////////////////////////////
//	HAL_TIM_Base_Start_IT(&htim6);
	/////////////////////////////////    LVGL_INIT  ///////////////////////////////
//	lv_init();
//	lv_port_disp_init();
//	HAL_Delay(1000);
	LCD_Init();
	__HAL_GPIO_EXTI_CLEAR_IT(TOUCH_I2C3_INT_Pin);
//	__HAL_TIM_CLEAR_IT(&htim6, TIM_IT_UPDATE);
	TOUCH_INIT();

//	for(uint8_t i=0;i<100;i++)
//	{
//		LCD_Draw_Point(i,i,RED);
//	}
//	lv_port_indev_init();
//  lv_fs_fatfs_init();
//	lv_demo_myself();
  /* USER CODE END 2 */

  /* Infinite loop */
  /* USER CODE BEGIN WHILE */
  while (1)
  {
//		lv_task_handler();
    /* USER CODE END WHILE */

  }
}

void SystemClock_Config(void)
{
  RCC_OscInitTypeDef RCC_OscInitStruct = {0};
  RCC_ClkInitTypeDef RCC_ClkInitStruct = {0};

  /** Supply configuration update enable
  */
  HAL_PWREx_ConfigSupply(PWR_LDO_SUPPLY);

  /** Configure the main internal regulator output voltage
  */
  __HAL_PWR_VOLTAGESCALING_CONFIG(PWR_REGULATOR_VOLTAGE_SCALE0);

  while(!__HAL_PWR_GET_FLAG(PWR_FLAG_VOSRDY)) {}

  /** Initializes the RCC Oscillators according to the specified parameters
  * in the RCC_OscInitTypeDef structure.
  */
  RCC_OscInitStruct.OscillatorType = RCC_OSCILLATORTYPE_HSI|RCC_OSCILLATORTYPE_HSE;
  RCC_OscInitStruct.HSEState = RCC_HSE_ON;
  RCC_OscInitStruct.HSIState = RCC_HSI_DIV1;
  RCC_OscInitStruct.HSICalibrationValue = 64;
  RCC_OscInitStruct.PLL.PLLState = RCC_PLL_ON;
  RCC_OscInitStruct.PLL.PLLSource = RCC_PLLSOURCE_HSE;
  RCC_OscInitStruct.PLL.PLLM = 5;
  RCC_OscInitStruct.PLL.PLLN = 110;
  RCC_OscInitStruct.PLL.PLLP = 1;
  RCC_OscInitStruct.PLL.PLLQ = 10;
  RCC_OscInitStruct.PLL.PLLR = 2;
  RCC_OscInitStruct.PLL.PLLRGE = RCC_PLL1VCIRANGE_2;
  RCC_OscInitStruct.PLL.PLLVCOSEL = RCC_PLL1VCOWIDE;
  RCC_OscInitStruct.PLL.PLLFRACN = 0;
  if (HAL_RCC_OscConfig(&RCC_OscInitStruct) != HAL_OK)
  {
    Error_Handler();
  }

  /** Initializes the CPU, AHB and APB buses clocks
  */
  RCC_ClkInitStruct.ClockType = RCC_CLOCKTYPE_HCLK|RCC_CLOCKTYPE_SYSCLK
                              |RCC_CLOCKTYPE_PCLK1|RCC_CLOCKTYPE_PCLK2
                              |RCC_CLOCKTYPE_D3PCLK1|RCC_CLOCKTYPE_D1PCLK1;
  RCC_ClkInitStruct.SYSCLKSource = RCC_SYSCLKSOURCE_PLLCLK;
  RCC_ClkInitStruct.SYSCLKDivider = RCC_SYSCLK_DIV1;
  RCC_ClkInitStruct.AHBCLKDivider = RCC_HCLK_DIV2;
  RCC_ClkInitStruct.APB3CLKDivider = RCC_APB3_DIV2;
  RCC_ClkInitStruct.APB1CLKDivider = RCC_APB1_DIV2;
  RCC_ClkInitStruct.APB2CLKDivider = RCC_APB2_DIV2;
  RCC_ClkInitStruct.APB4CLKDivider = RCC_APB4_DIV2;

  if (HAL_RCC_ClockConfig(&RCC_ClkInitStruct, FLASH_LATENCY_3) != HAL_OK)
  {
    Error_Handler();
  }
}

void PeriphCommonClock_Config(void)
{
  RCC_PeriphCLKInitTypeDef PeriphClkInitStruct = {0};

  /** Initializes the peripherals clock
  */
  PeriphClkInitStruct.PeriphClockSelection = RCC_PERIPHCLK_CKPER;
  PeriphClkInitStruct.CkperClockSelection = RCC_CLKPSOURCE_HSI;
  if (HAL_RCCEx_PeriphCLKConfig(&PeriphClkInitStruct) != HAL_OK)
  {
    Error_Handler();
  }
}

void Error_Handler(void)
{
  __disable_irq();
  while (1)
  {
  }
}
